# PIC32MK0128MCA048 register map
Vendor: Microchip
Registers are 32-bit, read-write, reset 0x0 unless marked. A register's access mark holds for its fields unless they carry their own. Addresses are absolute, and some are shared; only a register's first bit layout is shown; [hi:lo] are bit positions; {n}, {i} and the like mark numbered series.

## CMP4
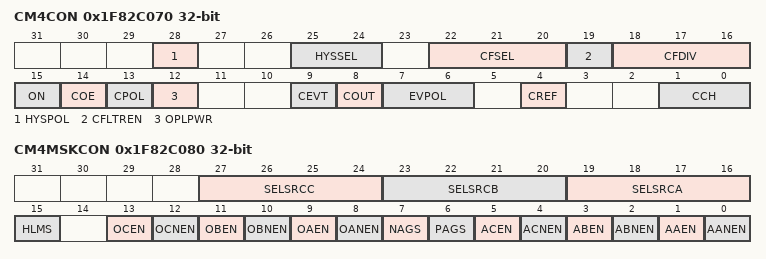
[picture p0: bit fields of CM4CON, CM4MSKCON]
0x1F82C070 CM4CON reset not defined — (power-on value ---x--00-00000000000--0000-0--00)
  [28] HYSPOL — Comparator Hysteresis Polarity Selection
    1=Hysteresis on falling edge, rising edge is accurate; 0=Hysteresis on rising edge, falling edge is accurate
  [25:24] HYSSEL
  [22:20] CFSEL
  [19] CFLTREN
  [18:16] CFDIV
  [15] ON
  [14] COE
  [13] CPOL
  [12] OPLPWR
  [9] CEVT
  [8] COUT ro
  [7:6] EVPOL
  [4] CREF
  [1:0] CCH
0x1F82C080 CM4MSKCON
  [27:24] SELSRCC, [23:20] SELSRCB, [19:16] SELSRCA, [15] HLMS, [13] OCEN, [12] OCNEN, [11] OBEN, [10] OBNEN, [9] OAEN, [8] OANEN, [7] NAGS, [6] PAGS, [5] ACEN, [4] ACNEN, [3] ABEN, [2] ABNEN, [1] AAEN, [0] AANEN

## CMP5
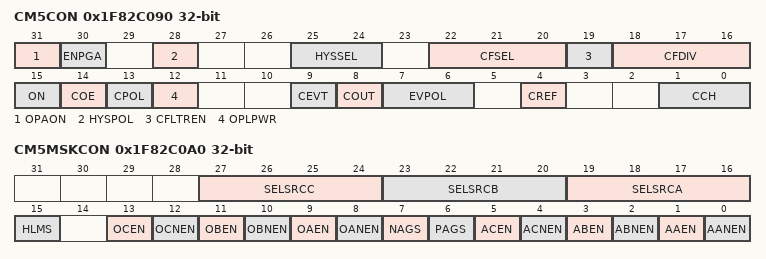
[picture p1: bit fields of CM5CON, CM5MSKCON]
0x1F82C090 CM5CON reset not defined — (power-on value xx-x--00-00000000000--0000-0--00)
  [31] OPAON — Opamp Enable Bit
    1=Opamp Enabled and Connected to Pin; 0=Opamp is disabled and pin is released to other functions
  [30] ENPGA — Opamp Fixed Gain Enable bit
    1=Op amp is operating in Fixed Gain 1X mode; 0=Op amp is operating in Open Loop Mode
  [28] HYSPOL — Comparator Hysteresis Polarity Selection
    1=Hysteresis on falling edge, rising edge is accurate; 0=Hysteresis on rising edge, falling edge is accurate
  [25:24] HYSSEL
  [22:20] CFSEL
  [19] CFLTREN
  [18:16] CFDIV
  [15] ON
  [14] COE
  [13] CPOL
  [12] OPLPWR
  [9] CEVT
  [8] COUT ro
  [7:6] EVPOL
  [4] CREF
  [1:0] CCH
0x1F82C0A0 CM5MSKCON
  [27:24] SELSRCC, [23:20] SELSRCB, [19:16] SELSRCA, [15] HLMS, [13] OCEN, [12] OCNEN, [11] OBEN, [10] OBNEN, [9] OAEN, [8] OANEN, [7] NAGS, [6] PAGS, [5] ACEN, [4] ACNEN, [3] ABEN, [2] ABNEN, [1] AAEN, [0] AANEN

## CDAC1
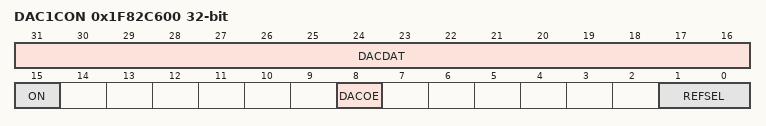
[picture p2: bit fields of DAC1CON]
0x1F82C600 DAC1CON — CDAC Control Register
  [31:16] DACDAT — Data Input Register Bits for the CDAC
  [15] ON — CDAC Enable
    0=The CDAC is Disabled; 1=The CDAC is Enabled
  [8] DACOE — CDAC Output Enable
    0=Output is Disabled; drive to pin is floating; 1=Output is Enabled; CDAC voltage is connected to the pin
  [1:0] REFSEL — Reference Source Select
    0=No Reference Selected (no current consumed); 1=Positive Reference Voltage = External Vref+ Pin; 2=Positive Reference Voltage = 2 * Internal Bandgap Reference Voltage; 3=Positive Reference Voltage = AVdd

## CTMU
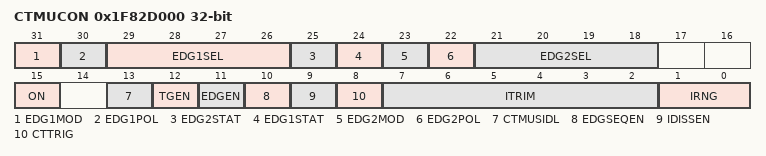
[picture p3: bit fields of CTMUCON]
0x1F82D000 CTMUCON
  [31] EDG1MOD, [30] EDG1POL, [29:26] EDG1SEL, [25] EDG2STAT, [24] EDG1STAT, [23] EDG2MOD, [22] EDG2POL, [21:18] EDG2SEL, [15] ON, [13] CTMUSIDL, [12] TGEN, [11] EDGEN, [10] EDGSEQEN, [9] IDISSEN, [8] CTTRIG, [7:2] ITRIM, [1:0] IRNG

## CLC1
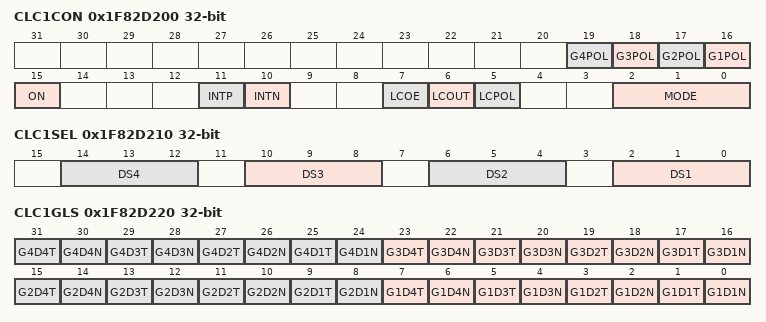
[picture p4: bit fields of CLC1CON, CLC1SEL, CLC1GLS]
0x1F82D200 CLC1CON
  [n+15] G{n}POL (n=1..4), [15] ON, [11] INTP, [10] INTN, [7] LCOE, [6] LCOUT, [5] LCPOL, [2:0] MODE
0x1F82D210 CLC1SEL
  [4n-2:4n-4] DS{n} (n=1..4)
0x1F82D220 CLC1GLS
  [8n-1] G{n}D4T (n=1..4), [8n-2] G{n}D4N (n=1..4), [8n-3] G{n}D3T (n=1..4), [8n-4] G{n}D3N (n=1..4), [8n-5] G{n}D2T (n=1..4), [8n-6] G{n}D2N (n=1..4), [8n-7] G{n}D1T (n=1..4), [8n-8] G{n}D1N (n=1..4)

## gpio_ports_upb
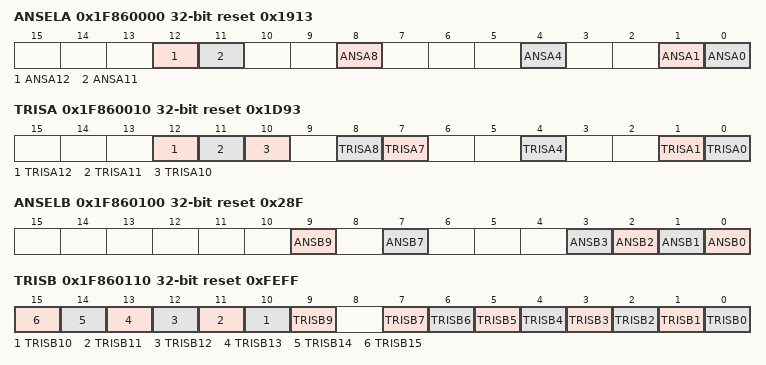
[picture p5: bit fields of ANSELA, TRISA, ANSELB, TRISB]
0x1F860000 ANSELA reset 0x1913
  [12] ANSA12, [11] ANSA11, [8] ANSA8, [4] ANSA4, [1] ANSA1, [0] ANSA0
0x1F860010 TRISA reset 0x1D93
  [12] TRISA12, [11] TRISA11, [10] TRISA10, [8] TRISA8, [7] TRISA7, [4] TRISA4, [1] TRISA1, [0] TRISA0
0x1F860100 ANSELB reset 0x28F
  [9] ANSB9, [7] ANSB7, [n] ANSB{n} (n=0..3)
0x1F860110 TRISB reset 0xFEFF
  [n] TRISB{n} (n=9..15), [n] TRISB{n} (n=0..7)
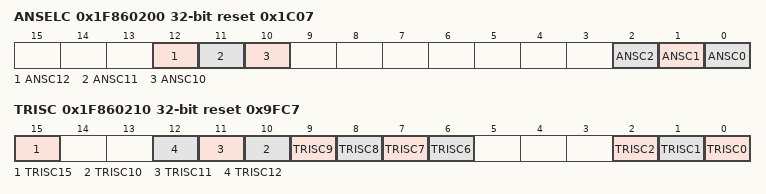
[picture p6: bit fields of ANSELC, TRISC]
0x1F860200 ANSELC reset 0x1C07
  [12] ANSC12, [11] ANSC11, [10] ANSC10, [2] ANSC2, [1] ANSC1, [0] ANSC0
0x1F860210 TRISC reset 0x9FC7
  [15] TRISC15, [n] TRISC{n} (n=6..12), [2] TRISC2, [1] TRISC1, [0] TRISC0
0x1F860300 ANSELD access not given reset not defined
0x1F860310 TRISD reset 0x100
  [8] TRISD8
